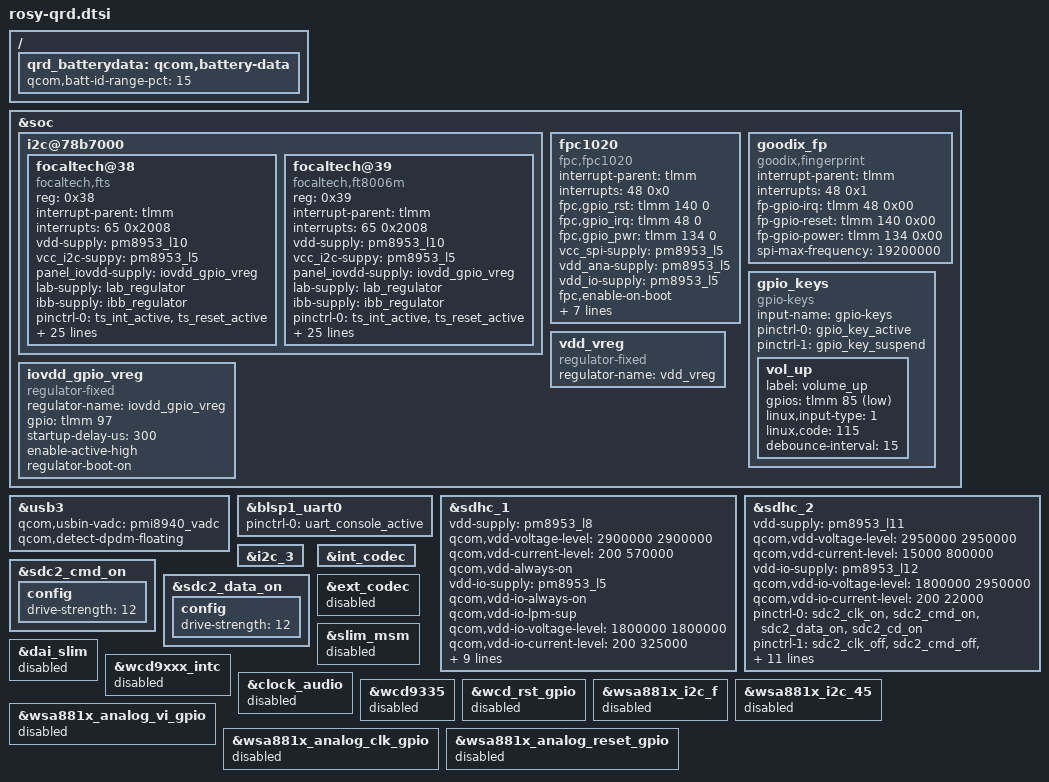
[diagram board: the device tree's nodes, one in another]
/*
 * Copyright (c) 2015-2019, The Linux Foundation. All rights reserved.
 * Copyright (C) 2019 XiaoMi, Inc.
 *
 * This program is free software; you can redistribute it and/or modify
 * it under the terms of the GNU General Public License version 2 and
 * only version 2 as published by the Free Software Foundation.
 *
 * This program is distributed in the hope that it will be useful,
 * but WITHOUT ANY WARRANTY; without even the implied warranty of
 * MERCHANTABILITY or FITNESS FOR A PARTICULAR PURPOSE.  See the
 * GNU General Public License for more details.
 */

&soc {
	i2c@78b7000 { /* BLSP1 QUP3 */
		status = "okay";

		focaltech@38 {
			compatible = "focaltech,fts";
			reg = <0x38>;
			interrupt-parent = <&tlmm>;
			interrupts = <65 0x2008>;
			vdd-supply = <&pm8953_l10>;
			vcc_i2c-suppy = <&pm8953_l5>;
			panel_iovdd-supply = <&iovdd_gpio_vreg>;
			lab-supply = <&lab_regulator>;
			ibb-supply = <&ibb_regulator>;
			/* pins used by touchscreen */
			pinctrl-names = "pmx_ts_active","pmx_ts_suspend",
						"pmx_ts_release";
			pinctrl-0 = <&ts_int_active &ts_reset_active>;
			pinctrl-1 = <&ts_int_suspend &ts_reset_suspend>;
			pinctrl-2 = <&ts_release>;
			focaltech,name = "fts_ts";
			focaltech,family-id = <0x54>;
			focaltech,reset-gpio = <&tlmm 64 0x00>;
			focaltech,irq-gpio = <&tlmm 65 0x2008>;
			focaltech,display-coords = <0 0 720 1440>;
			focaltech,panel-coords = <0 0 720 1440>;
			/*ftech,button-map= <139 102 158>;*/
			focaltech,virtual-key1 = <139 560 2000>;/*menu*/
			focaltech,virtual-key2 = <102 360 2000>;/*home*/
			focaltech,virtual-key3 = <158 160 2000>;/*back*/
			focaltech,no-force-update;
			focaltech,i2c-pull-up;
			focaltech,group-id = <1>;
			focaltech,hard-reset-delay-ms = <20>;
			focaltech,soft-reset-delay-ms = <200>;
			focaltech,num-max-touches = <10>;
			focaltech,fw-delay-aa-ms = <30>;
			focaltech,fw-delay-55-ms = <30>;
			focaltech,fw-upgrade-id1 = <0x79>;
			focaltech,fw-upgrade-id2 = <0x18>;
			focaltech,fw-delay-readid-ms = <10>;
			focaltech,fw-delay-era-flsh-ms = <2000>;
			focaltech,fw-auto-cal;
			focaltech,ignore-id-check;
		};

		focaltech@39 {
			compatible = "focaltech,ft8006m";
			reg = <0x39>;
			interrupt-parent = <&tlmm>;
			interrupts = <65 0x2008>;		            
			vdd-supply = <&pm8953_l10>;
			vcc_i2c-suppy = <&pm8953_l5>;
			panel_iovdd-supply = <&iovdd_gpio_vreg>;
			lab-supply = <&lab_regulator>;
			ibb-supply = <&ibb_regulator>;
			/* pins used by touchscreen */
			pinctrl-names = "pmx_ts_active","pmx_ts_suspend",
						"pmx_ts_release";
			pinctrl-0 = <&ts_int_active &ts_reset_active>;	
			pinctrl-1 = <&ts_int_suspend &ts_reset_suspend>;	
			pinctrl-2 = <&ts_release>;
			focaltech,name = "fts_ts";	
			focaltech,family-id = <0x54>;
			focaltech,reset-gpio = <&tlmm 64 0x00>;
			focaltech,irq-gpio = <&tlmm 65 0x2008>;
			focaltech,display-coords = <0 0 720 1440>;
			focaltech,panel-coords = <0 0 720 1440>;
			/*ftech,button-map= <139 102 158>;*/
			focaltech,virtual-key1 = <139 560 2000>;/*menu*/
			focaltech,virtual-key2 = <102 360 2000>;/*home*/
			focaltech,virtual-key3 = <158 160 2000>;/*back*/
			focaltech,no-force-update;
			focaltech,i2c-pull-up;
			focaltech,group-id = <1>;
			focaltech,hard-reset-delay-ms = <20>;
			focaltech,soft-reset-delay-ms = <200>;
			focaltech,num-max-touches = <10>;
			focaltech,fw-delay-aa-ms = <30>;
			focaltech,fw-delay-55-ms = <30>;
			focaltech,fw-upgrade-id1 = <0x79>;
			focaltech,fw-upgrade-id2 = <0x18>;
			focaltech,fw-delay-readid-ms = <10>;
			focaltech,fw-delay-era-flsh-ms = <2000>;
			focaltech,fw-auto-cal;
			focaltech,ignore-id-check;
		};
	};

	fpc1020 {
		compatible = "fpc,fpc1020";
		interrupt-parent = <&tlmm>;
		interrupts = <48 0x0>;
		fpc,gpio_rst    = <&tlmm 140 0>;
		fpc,gpio_irq    = <&tlmm 48 0>;
		fpc,gpio_pwr   = <&tlmm 134 0>;
		vcc_spi-supply  = <&pm8953_l5>;
		vdd_ana-supply  = <&pm8953_l5>;
		vdd_io-supply   = <&pm8953_l5>;
		fpc,enable-on-boot;
		/delete-property/ fpc,enable-wakeup;
		fpc,spi-max-frequency = <4800000>;
		/* Only for SPI Clock Handled by Linux */
		clock-names = "iface_clk", "core_clk";
		clocks = <&clock_gcc clk_gcc_blsp1_ahb_clk>,
				<&clock_gcc clk_gcc_blsp1_qup1_spi_apps_clk>;
		pinctrl-names = "fpc1020_spi_active",
						"fpc1020_reset_reset",
						"fpc1020_reset_active",
						"fpc1020_irq_active";
		pinctrl-0 = <&fpc_spi_active>;
		pinctrl-1 = <&fpc_reset_reset>;
		pinctrl-2 = <&fpc_reset_active>;
		pinctrl-3 = <&fpc_irq_active>;
	};

	goodix_fp {
		compatible = "goodix,fingerprint";
		interrupt-parent = <&tlmm>;
		interrupts = <48 0x1>;
		fp-gpio-irq = <&tlmm 48 0x00>;
		fp-gpio-reset = <&tlmm 140 0x00>;
		fp-gpio-power = <&tlmm 134 0x00>;
		spi-max-frequency = <19200000>;
	};

	gpio_keys {
		compatible = "gpio-keys";
		input-name = "gpio-keys";
		pinctrl-names = "tlmm_gpio_key_active","tlmm_gpio_key_suspend";
		pinctrl-0 = <&gpio_key_active>;
		pinctrl-1 = <&gpio_key_suspend>;

		vol_up {
			label = "volume_up";
			gpios = <&tlmm 85 0x1>;
			linux,input-type = <1>;
			linux,code = <115>;
			debounce-interval = <15>;
		};
	};

	vdd_vreg: vdd_vreg {
		compatible = "regulator-fixed";
		status = "ok";
		regulator-name = "vdd_vreg";
	};

	iovdd_gpio_vreg: iovdd_gpio_vreg {
		compatible = "regulator-fixed";
		regulator-name="iovdd_gpio_vreg";
		gpio = <&tlmm 97 0>; /* iovdd - ldo6 */
		startup-delay-us = <300>;
		enable-active-high;
		regulator-boot-on;
		status = "ok";
	};
};

/ {
	qrd_batterydata: qcom,battery-data {
		qcom,batt-id-range-pct = <15>;
		#include "battery/batterydata-Scud-4v4-3300mah.dtsi"
		#include "battery/batterydata-Sunwoda-4v4-3300mah.dtsi"
		#include "battery/batterydata-D1_Default-4v4-3300mah.dtsi"
	};
};

&usb3 {
	qcom,usbin-vadc = <&pmi8940_vadc>;
	qcom,detect-dpdm-floating;
};

&blsp1_uart0 {
	status = "ok";
	pinctrl-names = "default";
	pinctrl-0 = <&uart_console_active>;
};

&sdhc_1 {
	/* device core power supply */
	vdd-supply = <&pm8953_l8>;
	qcom,vdd-voltage-level = <2900000 2900000>;
	qcom,vdd-current-level = <200 570000>;
	qcom,vdd-always-on;

	/* device communication power supply */
	vdd-io-supply = <&pm8953_l5>;
	qcom,vdd-io-always-on;
	qcom,vdd-io-lpm-sup;
	qcom,vdd-io-voltage-level = <1800000 1800000>;
	qcom,vdd-io-current-level = <200 325000>;

	pinctrl-names = "active", "sleep";
	pinctrl-0 = <&sdc1_clk_on &sdc1_cmd_on &sdc1_data_on &sdc1_rclk_on>;
	pinctrl-1 = <&sdc1_clk_off &sdc1_cmd_off &sdc1_data_off &sdc1_rclk_off>;

	qcom,clk-rates = <400000 20000000 25000000 50000000 100000000 192000000
								384000000>;
	qcom,nonremovable;
	qcom,bus-speed-mode = "HS400_1p8v", "HS200_1p8v", "DDR_1p8v";

	status = "ok";
};

&sdhc_2 {
	/* device core power supply */
	vdd-supply = <&pm8953_l11>;
	qcom,vdd-voltage-level = <2950000 2950000>;
	qcom,vdd-current-level = <15000 800000>;

	/* device communication power supply */
	vdd-io-supply = <&pm8953_l12>;
	qcom,vdd-io-voltage-level = <1800000 2950000>;
	qcom,vdd-io-current-level = <200 22000>;

	pinctrl-names = "active", "sleep";
	pinctrl-0 = <&sdc2_clk_on &sdc2_cmd_on &sdc2_data_on &sdc2_cd_on>;
	pinctrl-1 = <&sdc2_clk_off &sdc2_cmd_off &sdc2_data_off &sdc2_cd_off>;

	#address-cells = <0>;
	interrupt-parent = <&sdhc_2>;
	interrupts = <0 1 2>;
	#interrupt-cells = <1>;
	interrupt-map-mask = <0xffffffff>;
	interrupt-map = <0 &intc 0 125 0
		1 &intc 0 221 0
		2 &tlmm 133 0>;
	interrupt-names = "hc_irq", "pwr_irq", "status_irq";
	cd-gpios = <&tlmm 133 0x0>;

	qcom,clk-rates = <400000 20000000 25000000 50000000 100000000
								200000000>;
	qcom,bus-speed-mode = "SDR12", "SDR25", "SDR50", "DDR50", "SDR104";

	status = "ok";
};

&i2c_3 {
	status = "ok";
};

&sdc2_cmd_on {
	config {
		drive-strength=<12>;
	};
};

&sdc2_data_on {
	config {
		drive-strength=<12>;
	};
};

&int_codec {
	status = "ok";
};

&ext_codec {
	status = "disabled";
};

&slim_msm {
	status = "disabled";
};

&dai_slim {
	status = "disabled";
};

&wcd9xxx_intc {
	status = "disabled";
};

&clock_audio {
	status = "disabled";
};

&wcd9335 {
	status = "disabled";
};

&wcd_rst_gpio {
	status = "disabled";
};

&wsa881x_i2c_f {
        status = "disabled";
};

&wsa881x_i2c_45 {
        status = "disabled";
};

&wsa881x_analog_vi_gpio {
        status = "disabled";
};

&wsa881x_analog_clk_gpio {
        status = "disabled";
};

&wsa881x_analog_reset_gpio {
        status = "disabled";
};
